# ATtiny3214 device description
Architecture: AVR8X; Family: AVR TINY
Registers are 8-bit, read-write, no defined reset value unless marked. A register's access mark holds for its fields unless they carry their own. Offsets are from the block's base; [hi:lo] are bit positions; 'fields as' and 'values as' point back to an identical list.

## BOD — Bod interface
Instances: BOD 0x0080
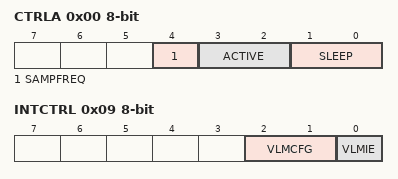
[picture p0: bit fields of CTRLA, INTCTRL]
0x00 CTRLA — Control A
  [4] SAMPFREQ ro — Sample frequency
    0=1KHZ (1kHz sampling frequency); 1=125HZ (125kHz sampling frequency)
  [3:2] ACTIVE ro — Operation in active mode
    0=OFF (Disabled); 1=ENABLED; 2=SAMPLED; 3=ENWAKE (Enabled with wake-up halted until BOD is ready)
  [1:0] SLEEP — Operation in sleep mode
    0=OFF (Disabled); 1=ENABLED; 2=SAMPLED
0x01 CTRLB — Control B
  [2:0] LVL ro — Bod level
    0=1V8 (1.8 V); 1=2V15 (2.15 V); 2=2V51 (2.51 V); 3=2V87 (2.87 V); 6=3V94 (3.94 V); 7=4V3 (4.3 V)
0x08 VLMCTRLA — Voltage level monitor Control
  [1:0] VLMLVL — voltage level monitor level
    0=5ABOVE (VLM threshold 5% above BOD level); 1=15ABOVE (VLM threshold 15% above BOD level); 2=25ABOVE (VLM threshold 25% above BOD level)
0x09 INTCTRL — Voltage level monitor interrupt Control
  [2:1] VLMCFG — Configuration
    0=BELOW (Interrupt when supply goes below VLM level); 1=ABOVE (Interrupt when supply goes above VLM level); 2=CROSS (Interrupt when supply crosses VLM level)
  [0] VLMIE — voltage level monitor interrrupt enable
0x0A INTFLAGS — Voltage level monitor interrupt Flags
  [0] VLMIF — Voltage level monitor interrupt flag
0x0B STATUS — Voltage level monitor status
  [0] VLMS ro

## CCL — Configurable Custom Logic
Instances: CCL 0x01C0
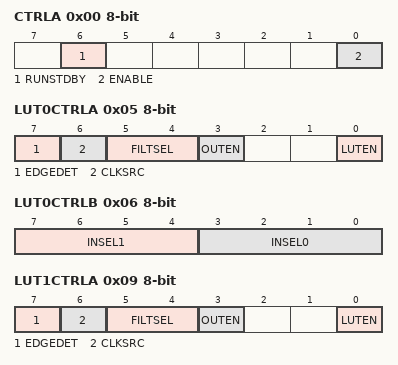
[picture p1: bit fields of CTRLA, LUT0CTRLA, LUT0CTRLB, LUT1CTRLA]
0x00 CTRLA — Control Register A
  [6] RUNSTDBY — Run in Standby
  [0] ENABLE
0x01 SEQCTRL0 — Sequential Control 0
  [2:0] SEQSEL — Sequential Selection
    0=DISABLE (Sequential logic disabled); 1=DFF (D FlipFlop); 2=JK (JK FlipFlop); 3=LATCH (D Latch); 4=RS (RS Latch)
0x05 LUT0CTRLA — LUT Control 0 A
  [7] EDGEDET — Edge Detection Enable
    0=DIS (Edge detector is disabled); 1=EN (Edge detector is enabled)
  [6] CLKSRC — Clock Source Selection
  [5:4] FILTSEL — Filter Selection
    0=DISABLE (Filter disabled); 1=SYNCH (Synchronizer enabled); 2=FILTER (Filter enabled)
  [3] OUTEN — Output Enable
  [0] LUTEN — LUT Enable
0x06 LUT0CTRLB — LUT Control 0 B
  [7:4] INSEL1 — LUT Input 1 Source Selection
    0=MASK (Masked input); 1=FEEDBACK (Feedback input source); 2=LINK (Linked LUT input source); 3=EVENT0 (Event input source 0); 4=EVENT1 (Event input source 1); 5=IO (IO pin LUTn-N1 input source); 6=AC0 (AC0 OUT input source); 7=TCB0 (TCB0 WO input source); 8=TCA0 (TCA0 WO1 input source); 9=TCD0 (TCD0 WO1 input source); 10=USART0 (USART0 TXD input source); 11=SPI0 (SPI0 MOSI input source)
  [3:0] INSEL0 — LUT Input 0 Source Selection
    0=MASK (Masked input); 1=FEEDBACK (Feedback input source); 2=LINK (Linked LUT input source); 3=EVENT0 (Event input source 0); 4=EVENT1 (Event input source 1); 5=IO (IO pin LUTn-IN0 input source); 6=AC0 (AC0 OUT input source); 7=TCB0 (TCB0 WO input source); 8=TCA0 (TCA0 WO0 input source); 9=TCD0 (TCD0 WO0 input source); 10=USART0 (USART0 XCK input source); 11=SPI0 (SPI0 SCK source)
0x07 LUT0CTRLC — LUT Control 0 C
  [3:0] INSEL2 — LUT Input 2 Source Selection
    0=MASK (Masked input); 1=FEEDBACK (Feedback input source); 2=LINK (Linked LUT input source); 3=EVENT0 (Event input source 0); 4=EVENT1 (Event input source 1); 5=IO (IO pin LUTn-IN2 input source); 6=AC0 (AC0 OUT input source); 7=TCB0 (TCB0 WO input source); 8=TCA0 (TCA0 WO2 input source); 9=TCD0 (TCD0 WO0 input source); 11=SPI0 (SPI0 MISO source)
0x08 TRUTH0
0x09 LUT1CTRLA — LUT Control 1 A
  fields as LUT0CTRLA
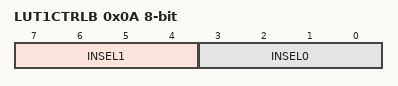
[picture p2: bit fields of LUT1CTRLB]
0x0A LUT1CTRLB — LUT Control 1 B
  fields as LUT0CTRLB
0x0B LUT1CTRLC — LUT Control 1 C
  fields as LUT0CTRLC
0x0C TRUTH1

## CLKCTRL — Clock controller
Instances: CLKCTRL 0x0060
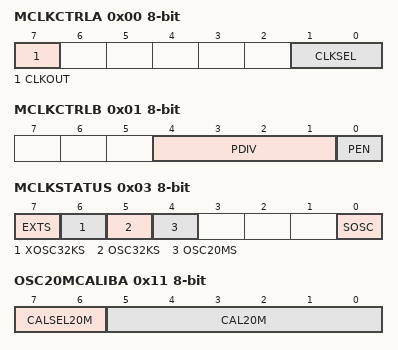
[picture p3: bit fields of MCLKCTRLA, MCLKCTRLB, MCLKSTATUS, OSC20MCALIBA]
0x00 MCLKCTRLA — MCLK Control A
  [7] CLKOUT — System clock out
  [1:0] CLKSEL — clock select
    0=OSC20M (20MHz internal oscillator); 1=OSCULP32K (32KHz internal Ultra Low Power oscillator); 2=XOSC32K (32.768kHz external crystal oscillator); 3=EXTCLK (External clock)
0x01 MCLKCTRLB — MCLK Control B
  [4:1] PDIV — Prescaler division
    0=2X; 1=4X; 2=8X; 3=16X; 4=32X; 5=64X; 8=6X; 9=10X; 10=12X; 11=24X; 12=48X
  [0] PEN — Prescaler enable
0x02 MCLKLOCK
  [0] LOCKEN — lock ebable
0x03 MCLKSTATUS
  [7] EXTS — External Clock status
  [6] XOSC32KS — 32.768 kHz Crystal Oscillator status
  [5] OSC32KS — 32KHz oscillator status
  [4] OSC20MS — 20MHz oscillator status
  [0] SOSC — System Oscillator changing
0x10 OSC20MCTRLA — OSC20M Control A
  [1] RUNSTDBY — Run standby
0x11 OSC20MCALIBA — OSC20M Calibration A
  [7:6] CALSEL20M — Calibration freq select
  [5:0] CAL20M — Calibration
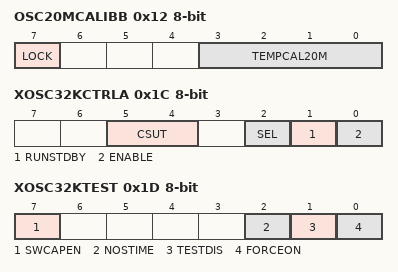
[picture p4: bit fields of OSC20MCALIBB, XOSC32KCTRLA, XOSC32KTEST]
0x12 OSC20MCALIBB — OSC20M Calibration B
  [7] LOCK
  [3:0] TEMPCAL20M — Oscillator temperature coefficient
0x18 OSC32KCTRLA — OSC32K Control A
  [1] RUNSTDBY — Run standby
0x1C XOSC32KCTRLA — XOSC32K Control A
  [5:4] CSUT — Crystal startup time
    0=1K (1K cycles); 1=16K (16K cycles); 2=32K (32K cycles); 3=64K (64K cycles)
  [2] SEL — Select
  [1] RUNSTDBY — Run standby
  [0] ENABLE
0x1D XOSC32KTEST
  [7] SWCAPEN — Switch cap mode enable
  [2] NOSTIME — No startup time
  [1] TESTDIS — Test disable
  [0] FORCEON
